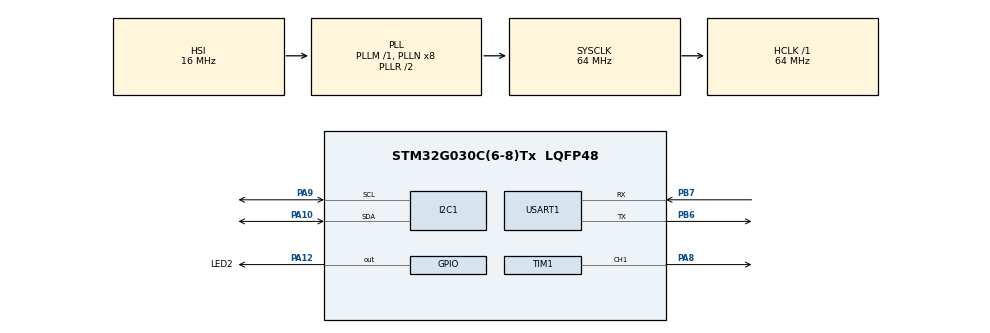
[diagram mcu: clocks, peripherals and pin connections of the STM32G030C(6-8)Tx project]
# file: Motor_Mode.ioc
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Dma.Request0=USART1_RX
Dma.Request1=USART1_TX
Dma.USART1_RX.0.Direction=DMA_PERIPH_TO_MEMORY
Dma.USART1_RX.0.EventEnable=DISABLE
Dma.USART1_RX.0.Instance=DMA1_Channel1
Dma.USART1_RX.0.MemDataAlignment=DMA_MDATAALIGN_BYTE
Dma.USART1_RX.0.MemInc=DMA_MINC_ENABLE
Dma.USART1_RX.0.Mode=DMA_CIRCULAR
Dma.USART1_RX.0.PeriphDataAlignment=DMA_PDATAALIGN_BYTE
Dma.USART1_RX.0.PeriphInc=DMA_PINC_DISABLE
Dma.USART1_RX.0.Polarity=HAL_DMAMUX_REQ_GEN_RISING
Dma.USART1_RX.0.Priority=DMA_PRIORITY_LOW
Dma.USART1_RX.0.RequestNumber=1
Dma.USART1_RX.0.SignalID=NONE
Dma.USART1_RX.0.SyncEnable=DISABLE
Dma.USART1_RX.0.SyncPolarity=HAL_DMAMUX_SYNC_NO_EVENT
Dma.USART1_RX.0.SyncRequestNumber=1
Dma.USART1_RX.0.SyncSignalID=NONE
Dma.USART1_TX.1.Direction=DMA_MEMORY_TO_PERIPH
Dma.USART1_TX.1.EventEnable=DISABLE
Dma.USART1_TX.1.Instance=DMA1_Channel2
Dma.USART1_TX.1.MemDataAlignment=DMA_MDATAALIGN_BYTE
Dma.USART1_TX.1.MemInc=DMA_MINC_ENABLE
Dma.USART1_TX.1.Mode=DMA_NORMAL
Dma.USART1_TX.1.PeriphDataAlignment=DMA_PDATAALIGN_BYTE
Dma.USART1_TX.1.PeriphInc=DMA_PINC_DISABLE
Dma.USART1_TX.1.Polarity=HAL_DMAMUX_REQ_GEN_RISING
Dma.USART1_TX.1.Priority=DMA_PRIORITY_LOW
Dma.USART1_TX.1.RequestNumber=1
Dma.USART1_TX.1.SignalID=NONE
Dma.USART1_TX.1.SyncEnable=DISABLE
Dma.USART1_TX.1.SyncPolarity=HAL_DMAMUX_SYNC_NO_EVENT
Dma.USART1_TX.1.SyncRequestNumber=1
Dma.USART1_TX.1.SyncSignalID=NONE
I2C1.Timing=0x10707DBC
Mcu.Family=STM32G0
Mcu.Name=STM32G030C(6-8)Tx
Mcu.Package=LQFP48
NVIC.DMA1_Channel1_IRQn=true\:0\:0\:false\:false\:true\:false\:true
NVIC.DMA1_Channel2_3_IRQn=true\:0\:0\:false\:false\:true\:false\:true
PA10.Mode=I2C
PA10.Signal=I2C1_SDA
PA12\ [PA10].GPIO_Label=LED2
PA12\ [PA10].Signal=GPIO_Output
PA13.Mode=Serial_Wire
PA13.Signal=SYS_SWDIO
PA14-BOOT0.Mode=Serial_Wire
PA14-BOOT0.Signal=SYS_SWCLK
PA8.Signal=S_TIM1_CH1
PA9.Mode=I2C
PA9.Signal=I2C1_SCL
PB6.GPIO_PuPd=GPIO_PULLUP
PB6.Mode=Asynchronous
PB6.Signal=USART1_TX
PB7.GPIO_PuPd=GPIO_PULLUP
PB7.Mode=Asynchronous
PB7.Signal=USART1_RX
PF0-OSC_IN\ (PF0).Mode=HSE-External-Oscillator
PF0-OSC_IN\ (PF0).Signal=RCC_OSC_IN
PF1-OSC_OUT\ (PF1).Mode=HSE-External-Oscillator
PF1-OSC_OUT\ (PF1).Signal=RCC_OSC_OUT
ProjectManager.HeapSize=0x200
ProjectManager.StackSize=0x400
ProjectManager.TargetToolchain=MDK-ARM V5
RCC.ADCFreq_Value=64000000
RCC.AHBFreq_Value=64000000
RCC.CortexFreq_Value=64000000
RCC.EXTERNAL_CLOCK_VALUE=12288000
RCC.HCLKFreq_Value=64000000
RCC.HSE_VALUE=8000000
RCC.HSI_VALUE=16000000
RCC.LSE_VALUE=32768
RCC.SYSCLKFreq_VALUE=64000000
RCC.SYSCLKSource=RCC_SYSCLKSOURCE_PLLCLK
RCC.VCOOutputFreq_Value=128000000
SH.S_TIM1_CH1.0=TIM1_CH1,PWM Generation1 CH1
TIM1.AutoReloadPreload=TIM_AUTORELOAD_PRELOAD_DISABLE
TIM1.Channel-PWM\ Generation1\ CH1=TIM_CHANNEL_1
TIM1.Period=19999
TIM1.Prescaler=63
USART1.VirtualMode-Asynchronous=VM_ASYNC
board=custom

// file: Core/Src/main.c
/* USER CODE BEGIN Header */
/**
  ******************************************************************************
  * @file           : main.c
  * @brief          : Main program body
  ******************************************************************************
  * @attention
  *
  * Copyright (c) 2022 STMicroelectronics.
  * All rights reserved.
  *
  * This software is licensed under terms that can be found in the LICENSE file
  * in the root directory of this software component.
  * If no LICENSE file comes with this software, it is provided AS-IS.
  *
  ******************************************************************************
  */
/* USER CODE END Header */
#include "main.h"
#include "dma.h"
#include "i2c.h"
#include "tim.h"
#include "usart.h"
#include "gpio.h"

void SystemClock_Config(void);

int main(void)
{

  /* MCU Configuration--------------------------------------------------------*/

  /* Reset of all peripherals, Initializes the Flash interface and the Systick. */
  HAL_Init();

  /* Configure the system clock */
  SystemClock_Config();

  /* Initialize all configured peripherals */
  MX_GPIO_Init();
  MX_DMA_Init();
  MX_I2C1_Init();
  MX_TIM1_Init();
  MX_USART1_UART_Init();
  /* USER CODE BEGIN 2 */

  //-----Init the motor (PWM)
  HAL_TIM_PWM_Start(&htim1,TIM_CHANNEL_1);
  __HAL_TIM_SET_COMPARE(&htim1,TIM_CHANNEL_1,500);
  HAL_Delay(1500);
  __HAL_TIM_SET_COMPARE(&htim1,TIM_CHANNEL_1,2500);
  HAL_Delay(1500);

  /* USER CODE END 2 */

  /* Infinite loop */
  /* USER CODE BEGIN WHILE */
  while (1)
  {
    HAL_GPIO_TogglePin(GPIOA,LED2_Pin);
    // HAL_Delay(100);

    //----- Motor part
    __HAL_TIM_SET_COMPARE(&htim1,TIM_CHANNEL_1,500);
    HAL_Delay(2000);
    __HAL_TIM_SET_COMPARE(&htim1,TIM_CHANNEL_1,2500);
    HAL_Delay(2000);

    /* USER CODE END WHILE */

  }
}

void SystemClock_Config(void)
{
  RCC_OscInitTypeDef RCC_OscInitStruct = {0};
  RCC_ClkInitTypeDef RCC_ClkInitStruct = {0};

  /** Configure the main internal regulator output voltage
  */
  HAL_PWREx_ControlVoltageScaling(PWR_REGULATOR_VOLTAGE_SCALE1);
  /** Initializes the RCC Oscillators according to the specified parameters
  * in the RCC_OscInitTypeDef structure.
  */
  RCC_OscInitStruct.OscillatorType = RCC_OSCILLATORTYPE_HSI;
  RCC_OscInitStruct.HSIState = RCC_HSI_ON;
  RCC_OscInitStruct.HSIDiv = RCC_HSI_DIV1;
  RCC_OscInitStruct.HSICalibrationValue = RCC_HSICALIBRATION_DEFAULT;
  RCC_OscInitStruct.PLL.PLLState = RCC_PLL_ON;
  RCC_OscInitStruct.PLL.PLLSource = RCC_PLLSOURCE_HSI;
  RCC_OscInitStruct.PLL.PLLM = RCC_PLLM_DIV1;
  RCC_OscInitStruct.PLL.PLLN = 8;
  RCC_OscInitStruct.PLL.PLLP = RCC_PLLP_DIV2;
  RCC_OscInitStruct.PLL.PLLR = RCC_PLLR_DIV2;
  if (HAL_RCC_OscConfig(&RCC_OscInitStruct) != HAL_OK)
  {
    Error_Handler();
  }
  /** Initializes the CPU, AHB and APB buses clocks
  */
  RCC_ClkInitStruct.ClockType = RCC_CLOCKTYPE_HCLK|RCC_CLOCKTYPE_SYSCLK
                              |RCC_CLOCKTYPE_PCLK1;
  RCC_ClkInitStruct.SYSCLKSource = RCC_SYSCLKSOURCE_PLLCLK;
  RCC_ClkInitStruct.AHBCLKDivider = RCC_SYSCLK_DIV1;
  RCC_ClkInitStruct.APB1CLKDivider = RCC_HCLK_DIV1;

  if (HAL_RCC_ClockConfig(&RCC_ClkInitStruct, FLASH_LATENCY_2) != HAL_OK)
  {
    Error_Handler();
  }
}

void Error_Handler(void)
{
  __disable_irq();
  while (1)
  {
  }
}
